# STM32F756ZGY6 register map
File version: 1.0
Registers are 32-bit, access not given, reset 0x0 unless marked. A register's access mark holds for its fields unless they carry their own. Offsets are from the block's base; [hi:lo] are bit positions; {n}, {i} and the like mark numbered series; 'fields as' and 'values as' point back to an identical list.

## HASH
Base 0x50060400
0x00 CR
  [16] LKEY, [13] MDMAT, [12] DINNE, [11:8] NBW, [18:7] ALGO, [6] MODE, [5:4] DATATYPE, [3] DMAE, [2] INIT
0x04 DIN
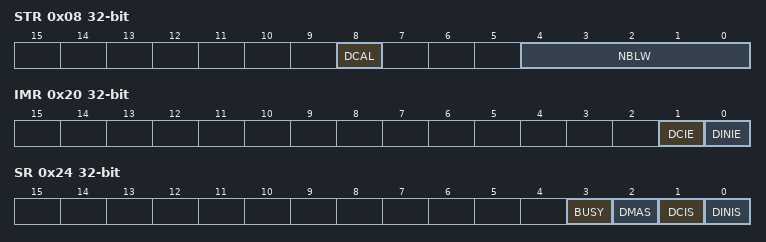
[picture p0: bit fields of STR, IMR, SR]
0x08 STR
  [8] DCAL, [4:0] NBLW
0x0C HR.0
0x10 HR.1
0x14 HR.2
0x18 HR.3
0x1C HR.4
0x20 IMR
  [1] DCIE, [0] DINIE
0x24 SR
  [3] BUSY, [2] DMAS, [1] DCIS, [0] DINIS
0xF8 CSR.0
0xFC CSR.1
0x100 CSR.2
0x104 CSR.3
0x108 CSR.4
0x10C CSR.5
0x110 CSR.6
0x114 CSR.7
0x118 CSR.8
0x11C CSR.9
0x120 CSR.10
0x124 CSR.11
0x128 CSR.12
0x12C CSR.13
0x130 CSR.14
0x134 CSR.15
0x138 CSR.16
0x13C CSR.17
0x140 CSR.18
0x144 CSR.19
0x148 CSR.20
0x14C CSR.21
0x150 CSR.22
0x154 CSR.23
0x158 CSR.24
0x15C CSR.25
0x160 CSR.26
0x164 CSR.27
0x168 CSR.28
0x16C CSR.29
0x170 CSR.30
0x174 CSR.31
0x178 CSR.32
0x17C CSR.33
0x180 CSR.34
0x184 CSR.35
0x188 CSR.36
0x18C CSR.37
0x190 CSR.38
0x194 CSR.39
0x198 CSR.40
0x19C CSR.41
0x1A0 CSR.42
0x1A4 CSR.43
0x1A8 CSR.44
0x1AC CSR.45
0x1B0 CSR.46
0x1B4 CSR.47
0x1B8 CSR.48
0x1BC CSR.49
0x1C0 CSR.50
0x1C4 CSR.51
0x1C8 CSR.52
0x1CC CSR.53

## HASH_DIGEST
Base 0x50060710
0x00 HR.0
0x04 HR.1
0x08 HR.2
0x0C HR.3
0x10 HR.4
0x14 HR.5
0x18 HR.6
0x1C HR.7

## RNG
Base 0x50060800
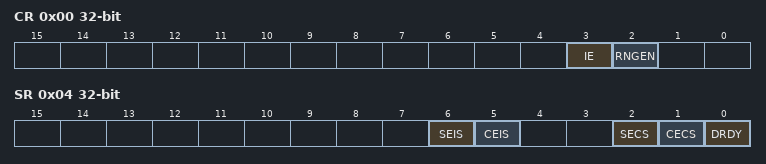
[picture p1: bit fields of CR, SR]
0x00 CR
  [3] IE, [2] RNGEN
0x04 SR
  [6] SEIS, [5] CEIS, [2] SECS, [1] CECS, [0] DRDY
0x08 DR

## FMC_Bank1
Base 0xA0000000
0x00 BTCR.0
0x04 BTCR.1
0x08 BTCR.2
0x0C BTCR.3
0x10 BTCR.4
0x14 BTCR.5
0x18 BTCR.6
0x1C BTCR.7

## FMC_Bank3
Base 0xA0000080
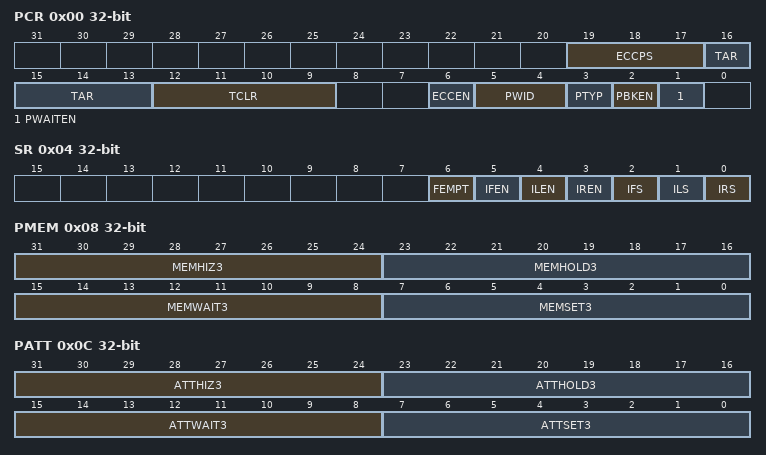
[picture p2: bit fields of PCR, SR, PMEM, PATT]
0x00 PCR
  [19:17] ECCPS, [16:13] TAR, [12:9] TCLR, [6] ECCEN, [5:4] PWID, [3] PTYP, [2] PBKEN, [1] PWAITEN
0x04 SR
  [6] FEMPT, [5] IFEN, [4] ILEN, [3] IREN, [2] IFS, [1] ILS, [0] IRS
0x08 PMEM
  [31:24] MEMHIZ3, [23:16] MEMHOLD3, [15:8] MEMWAIT3, [7:0] MEMSET3
0x0C PATT
  [31:24] ATTHIZ3, [23:16] ATTHOLD3, [15:8] ATTWAIT3, [7:0] ATTSET3
0x14 ECCR
  [31:0] ECC3

## FMC_Bank1E
Base 0xA0000104
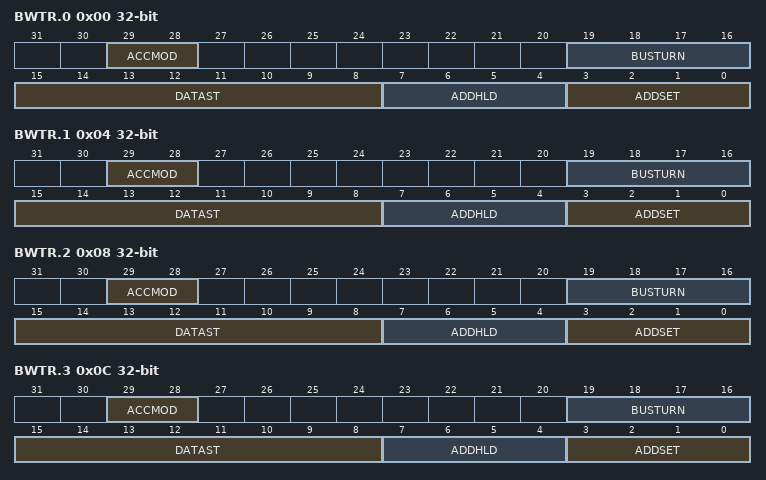
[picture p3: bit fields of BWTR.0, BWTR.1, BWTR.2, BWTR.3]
0x00 BWTR.0
  [29:28] ACCMOD, [19:16] BUSTURN, [15:8] DATAST, [7:4] ADDHLD, [3:0] ADDSET
0x04 BWTR.1
  fields as BWTR.0
0x08 BWTR.2
  fields as BWTR.0
0x0C BWTR.3
  fields as BWTR.0
0x10 BWTR.4
0x14 BWTR.5
0x18 BWTR.6

## FMC_Bank5_6
Base 0xA0000140
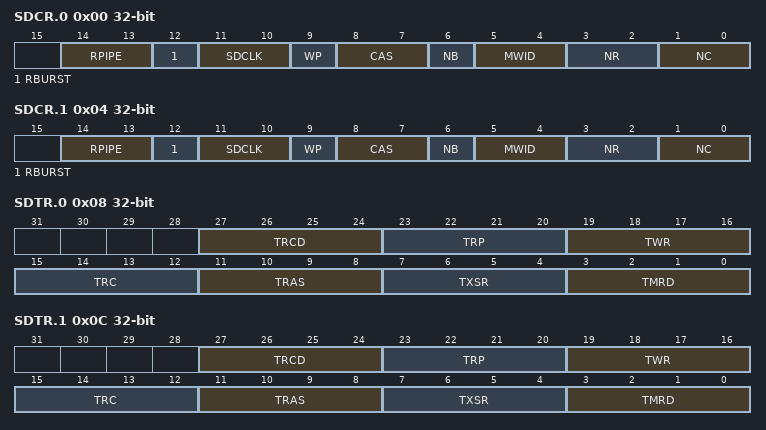
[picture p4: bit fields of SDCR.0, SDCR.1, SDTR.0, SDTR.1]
0x00 SDCR.0
  [14:13] RPIPE, [12] RBURST, [11:10] SDCLK, [9] WP, [8:7] CAS, [6] NB, [5:4] MWID, [3:2] NR, [1:0] NC
0x04 SDCR.1
  fields as SDCR.0
0x08 SDTR.0
  [27:24] TRCD, [23:20] TRP, [19:16] TWR, [15:12] TRC, [11:8] TRAS, [7:4] TXSR, [3:0] TMRD
0x0C SDTR.1
  fields as SDTR.0
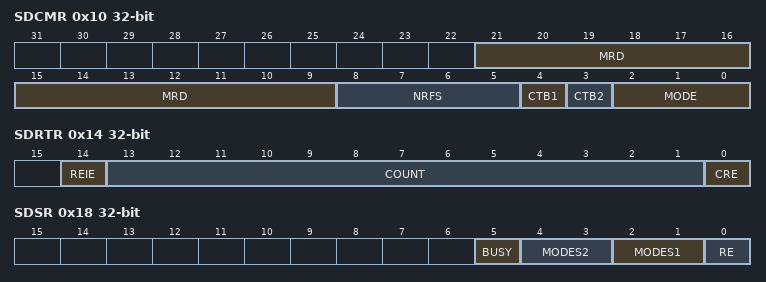
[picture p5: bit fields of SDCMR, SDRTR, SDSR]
0x10 SDCMR
  [21:9] MRD, [8:5] NRFS, [4] CTB1, [3] CTB2, [2:0] MODE
0x14 SDRTR
  [14] REIE, [13:1] COUNT, [0] CRE
0x18 SDSR
  [5] BUSY, [4:3] MODES2, [2:1] MODES1, [0] RE

## QUADSPI
Base 0xA0001000
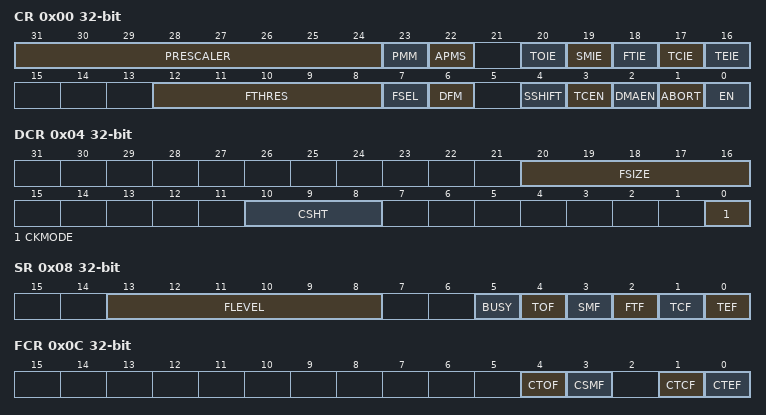
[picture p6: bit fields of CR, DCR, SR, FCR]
0x00 CR
  [31:24] PRESCALER, [23] PMM, [22] APMS, [20] TOIE, [19] SMIE, [18] FTIE, [17] TCIE, [16] TEIE, [12:8] FTHRES, [7] FSEL, [6] DFM, [4] SSHIFT, [3] TCEN, [2] DMAEN, [1] ABORT, [0] EN
0x04 DCR
  [20:16] FSIZE, [10:8] CSHT, [0] CKMODE
0x08 SR
  [13:8] FLEVEL, [5] BUSY, [4] TOF, [3] SMF, [2] FTF, [1] TCF, [0] TEF
0x0C FCR
  [4] CTOF, [3] CSMF, [1] CTCF, [0] CTEF
0x10 DLR
  [31:0] DL
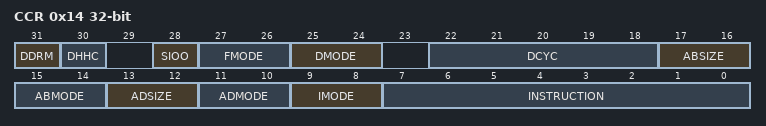
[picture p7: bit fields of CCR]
0x14 CCR
  [31] DDRM, [30] DHHC, [28] SIOO, [27:26] FMODE, [25:24] DMODE, [22:18] DCYC, [17:16] ABSIZE, [15:14] ABMODE, [13:12] ADSIZE, [11:10] ADMODE, [9:8] IMODE, [7:0] INSTRUCTION
0x18 AR
  [31:0] ADDRESS
0x1C ABR
  [31:0] ALTERNATE
0x20 DR
  [31:0] DATA
0x24 PSMKR
  [31:0] MASK
0x28 PSMAR
  [31:0] MATCH
0x2C PIR
  [15:0] INTERVAL
0x30 LPTR
  [15:0] TIMEOUT

## DBGMCU
Base 0xE0042000
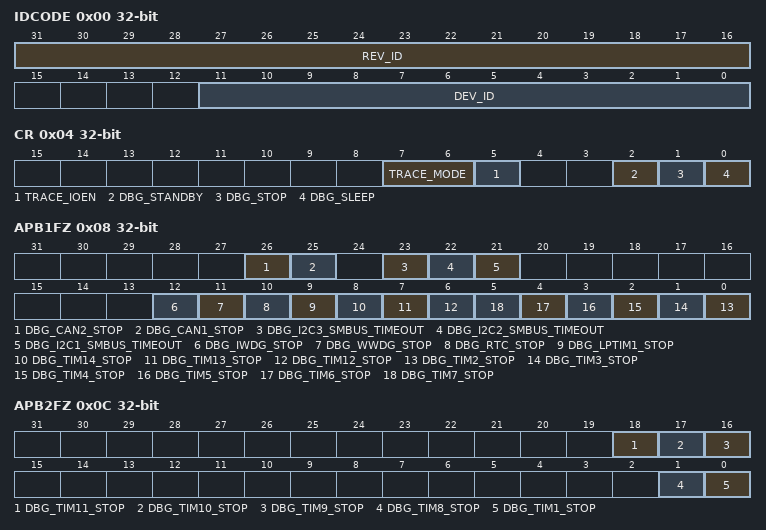
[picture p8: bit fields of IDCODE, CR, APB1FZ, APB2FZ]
0x00 IDCODE
  [31:16] REV_ID, [11:0] DEV_ID
0x04 CR
  [7:6] TRACE_MODE, [5] TRACE_IOEN, [2] DBG_STANDBY, [1] DBG_STOP, [0] DBG_SLEEP
0x08 APB1FZ
  [26] DBG_CAN2_STOP, [25] DBG_CAN1_STOP, [23] DBG_I2C3_SMBUS_TIMEOUT, [22] DBG_I2C2_SMBUS_TIMEOUT, [21] DBG_I2C1_SMBUS_TIMEOUT, [12] DBG_IWDG_STOP, [11] DBG_WWDG_STOP, [10] DBG_RTC_STOP, [9] DBG_LPTIM1_STOP, [8] DBG_TIM14_STOP, [7] DBG_TIM13_STOP, [6] DBG_TIM12_STOP, [n-2] DBG_TIM{n}_STOP (n=2..7)
0x0C APB2FZ
  [18] DBG_TIM11_STOP, [17] DBG_TIM10_STOP, [16] DBG_TIM9_STOP, [1] DBG_TIM8_STOP, [0] DBG_TIM1_STOP
